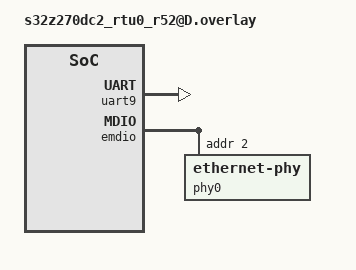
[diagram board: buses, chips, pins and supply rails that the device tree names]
/*
 * Copyright (c) 2024-2025, Arm Limited.
 * SPDX-License-Identifier: Apache-2.0
 */

/*
 * ARM Automotive Kit UART configuration
 * Uses UART9 instead of UART0 for console output
 * Required for ARM board vs standard NXP evaluation board
 */

/ {
	chosen {
		zephyr,console = &uart9;
		zephyr,shell-uart = &uart9;
		zephyr,canbus = &can0;
	};
};

&uart9 {
	pinctrl-0 = <&uart9_default>;
	pinctrl-names = "default";
	status = "okay";
};

&emdio {
    /delete-node/ ethernet-phy@7;

    phy0: ethernet-phy@2 {
        compatible = "ethernet-phy";
        reg = <0x2>;
        status = "okay";
    };
};
